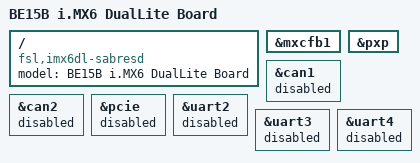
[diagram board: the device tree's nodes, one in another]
/*
 * Copyright (C) 2015 Exor S.p.a
 * 
 * Written by: G. Pavoni Exor S.p.a. (starting from the imx6dl_sabresd.dts file)
 * 
 * Copyright (C) 2013 Freescale Semiconductor, Inc.
 *
 * This program is free software; you can redistribute it and/or modify
 * it under the terms of the GNU General Public License version 2 as
 * published by the Free Software Foundation.
 */

/dts-v1/;

#include "imx6dl.dtsi"
#include "imx6usom_be15a.dtsi"

/ {
	model = "BE15B i.MX6 DualLite Board";
	compatible = "fsl,imx6dl-sabresd", "fsl,imx6dl";
};

&mxcfb1 {
	status = "okay";
};

&pxp {
	status = "okay";
};

&can1 {
	status = "disabled";
};

&can2 {
	status = "disabled";
};

&pcie {
	status = "disabled";
};

&uart2 {
	status = "disabled";
};

&uart3 {
	status = "disabled";
};

&uart4 {
	status = "disabled";
};
